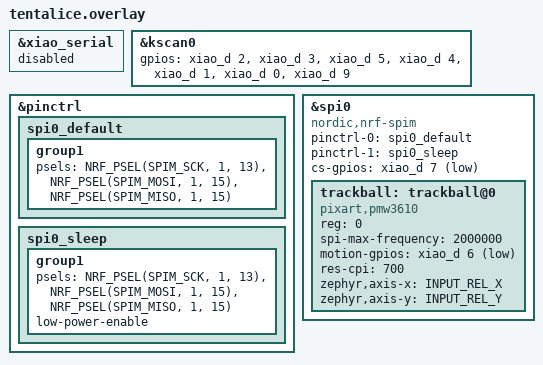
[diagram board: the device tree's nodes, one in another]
#include "tentalice.dtsi"

&xiao_serial { status = "disabled"; };

&kscan0 {
	gpios
		= <&xiao_d 2 (GPIO_ACTIVE_HIGH)>
		, <&xiao_d 3 (GPIO_ACTIVE_HIGH)>
		, <&xiao_d 5 (GPIO_ACTIVE_HIGH)>
		, <&xiao_d 4 (GPIO_ACTIVE_HIGH)>
		, <&xiao_d 1 (GPIO_ACTIVE_HIGH)>
		, <&xiao_d 0 (GPIO_ACTIVE_HIGH)>
		, <&xiao_d 9 (GPIO_ACTIVE_HIGH)>
		;

};

&pinctrl {
    spi0_default: spi0_default {
        group1 {
            psels = <NRF_PSEL(SPIM_SCK, 1, 13)>,
                <NRF_PSEL(SPIM_MOSI, 1, 15)>,
                <NRF_PSEL(SPIM_MISO, 1, 15)>;
        };
    };

    spi0_sleep: spi0_sleep {
        group1 {
            psels = <NRF_PSEL(SPIM_SCK, 1, 13)>,
                <NRF_PSEL(SPIM_MOSI, 1, 15)>,
                <NRF_PSEL(SPIM_MISO, 1, 15)>;
            low-power-enable;
        };
    };
};

#include <zephyr/dt-bindings/input/input-event-codes.h>

&spi0 {
    status = "okay";
    compatible = "nordic,nrf-spim";
    pinctrl-0 = <&spi0_default>;
    pinctrl-1 = <&spi0_sleep>;
    pinctrl-names = "default", "sleep";
    cs-gpios = <&xiao_d 7 GPIO_ACTIVE_LOW>;

    trackball: trackball@0 {
        status = "okay";
        compatible = "pixart,pmw3610"; 
        reg = <0>;
        spi-max-frequency = <2000000>;
        motion-gpios = <&xiao_d 6 (GPIO_ACTIVE_LOW | GPIO_PULL_UP)>;
        res-cpi = <700>;
        zephyr,axis-x = <INPUT_REL_X>;
        zephyr,axis-y = <INPUT_REL_Y>;
    };
};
